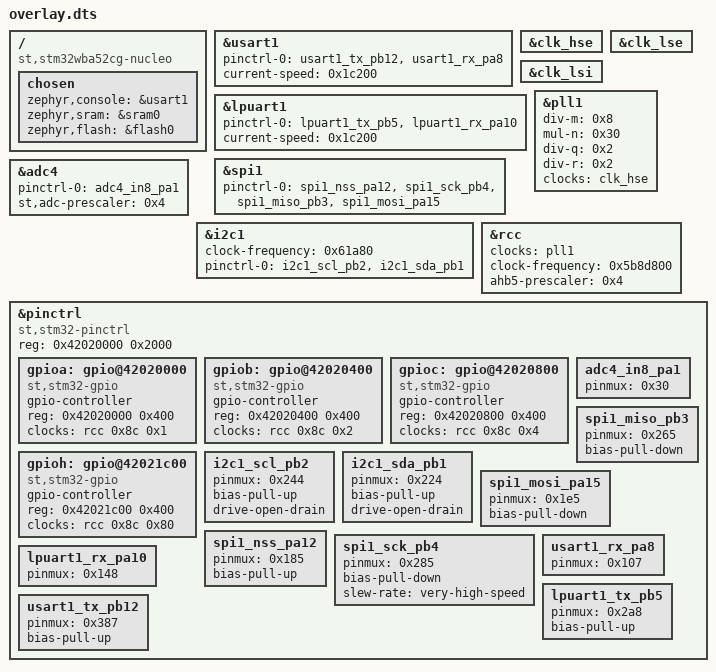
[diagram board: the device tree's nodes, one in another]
/ {
	compatible = "st,stm32wba52cg-nucleo";
	chosen {
		zephyr,console = &usart1;
		zephyr,sram = &sram0;
		zephyr,flash = &flash0;
	};
};
&usart1{
	status = "okay";
	pinctrl-0 = < &usart1_tx_pb12 &usart1_rx_pa8 >;
	pinctrl-names = "default";
	current-speed = < 0x1c200 >;
};
&clk_hse{
	status = "okay";
};
&clk_lse{
	status = "okay";
};
&clk_lsi{
	status = "okay";
};
&lpuart1{
	status = "okay";
	pinctrl-0 = < &lpuart1_tx_pb5 &lpuart1_rx_pa10 >;
	pinctrl-names = "default";
	current-speed = < 0x1c200 >;
};
&spi1{
	status = "okay";
	pinctrl-0 = < &spi1_nss_pa12 &spi1_sck_pb4 &spi1_miso_pb3 &spi1_mosi_pa15 >;
	pinctrl-names = "default";
};
&pll1{
	status = "okay";
	div-m = < 0x8 >;
	mul-n = < 0x30 >;
	div-q = < 0x2 >;
	div-r = < 0x2 >;
	clocks = < &clk_hse >;
};
&adc4{
	status = "okay";
	pinctrl-0 = < &adc4_in8_pa1 >;
	pinctrl-names = "default";
	st,adc-prescaler = < 0x4 >;
};
&i2c1{
	clock-frequency = < 0x61a80 >;
	status = "okay";
	pinctrl-0 = < &i2c1_scl_pb2 &i2c1_sda_pb1 >;
	pinctrl-names = "default";
};
&rcc{
	clocks = < &pll1 >;
	clock-frequency = < 0x5b8d800 >;
	ahb5-prescaler = < 0x4 >;
};
&pinctrl{
	compatible = "st,stm32-pinctrl";
	#address-cells = < 0x1 >;
	#size-cells = < 0x1 >;
	reg = < 0x42020000 0x2000 >;
	gpioa: gpio@42020000 {
		compatible = "st,stm32-gpio";
		gpio-controller;
		#gpio-cells = < 0x2 >;
		reg = < 0x42020000 0x400 >;
		clocks = < &rcc 0x8c 0x1 >;
	};
	gpiob: gpio@42020400 {
		compatible = "st,stm32-gpio";
		gpio-controller;
		#gpio-cells = < 0x2 >;
		reg = < 0x42020400 0x400 >;
		clocks = < &rcc 0x8c 0x2 >;
	};
	gpioc: gpio@42020800 {
		compatible = "st,stm32-gpio";
		gpio-controller;
		#gpio-cells = < 0x2 >;
		reg = < 0x42020800 0x400 >;
		clocks = < &rcc 0x8c 0x4 >;
	};
	gpioh: gpio@42021c00 {
		compatible = "st,stm32-gpio";
		gpio-controller;
		#gpio-cells = < 0x2 >;
		reg = < 0x42021c00 0x400 >;
		clocks = < &rcc 0x8c 0x80 >;
	};
	adc4_in8_pa1: adc4_in8_pa1 {
		pinmux = < 0x30 >;
	};
	i2c1_scl_pb2: i2c1_scl_pb2 {
		pinmux = < 0x244 >;
		bias-pull-up;
		drive-open-drain;
	};
	i2c1_sda_pb1: i2c1_sda_pb1 {
		pinmux = < 0x224 >;
		bias-pull-up;
		drive-open-drain;
	};
	spi1_miso_pb3: spi1_miso_pb3 {
		pinmux = < 0x265 >;
		bias-pull-down;
	};
	spi1_mosi_pa15: spi1_mosi_pa15 {
		pinmux = < 0x1e5 >;
		bias-pull-down;
	};
	spi1_nss_pa12: spi1_nss_pa12 {
		pinmux = < 0x185 >;
		bias-pull-up;
	};
	spi1_sck_pb4: spi1_sck_pb4 {
		pinmux = < 0x285 >;
		bias-pull-down;
		slew-rate = "very-high-speed";
	};
	usart1_rx_pa8: usart1_rx_pa8 {
		pinmux = < 0x107 >;
	};
	lpuart1_rx_pa10: lpuart1_rx_pa10 {
		pinmux = < 0x148 >;
	};
	lpuart1_tx_pb5: lpuart1_tx_pb5 {
		pinmux = < 0x2a8 >;
		bias-pull-up;
	};
	usart1_tx_pb12: usart1_tx_pb12 {
		pinmux = < 0x387 >;
		bias-pull-up;
	};
};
